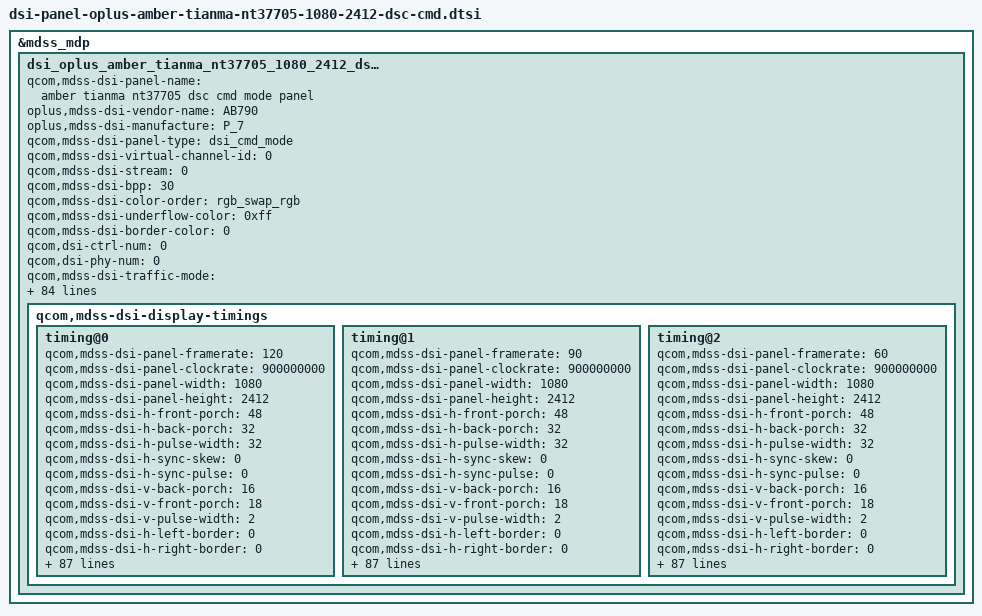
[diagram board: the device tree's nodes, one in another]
&mdss_mdp {
	dsi_oplus_amber_tianma_nt37705_1080_2412_dsc_cmd: qcom,mdss_dsi_oplus_amber_tianma_nt37705_1080_2412_dsc_cmd {
		qcom,mdss-dsi-panel-name = "amber tianma nt37705 dsc cmd mode panel";
		oplus,mdss-dsi-vendor-name = "AB790";
		oplus,mdss-dsi-manufacture = "P_7";
		qcom,mdss-dsi-panel-type = "dsi_cmd_mode";
		qcom,mdss-dsi-virtual-channel-id = <0>;
		qcom,mdss-dsi-stream = <0>;
		qcom,mdss-dsi-bpp = <30>;
		qcom,mdss-dsi-color-order = "rgb_swap_rgb";
		qcom,mdss-dsi-underflow-color = <0xff>;
		qcom,mdss-dsi-border-color = <0>;
		qcom,dsi-ctrl-num = <0>;
		qcom,dsi-phy-num = <0>;
		qcom,mdss-dsi-traffic-mode = "non_burst_sync_event";
		qcom,mdss-dsi-lane-map = "lane_map_0123";
		qcom,mdss-dsi-bllp-eof-power-mode;
		qcom,mdss-dsi-bllp-power-mode;
		qcom,mdss-dsi-lane-0-state;
		qcom,mdss-dsi-lane-1-state;
		qcom,mdss-dsi-lane-2-state;
		qcom,mdss-dsi-lane-3-state;
		qcom,mdss-dsi-dma-trigger = "trigger_sw";
		qcom,mdss-dsi-mdp-trigger = "none";
		qcom,mdss-dsi-reset-sequence = <1 10>, <0 10>, <1 20>;

		qcom,mdss-dsi-te-pin-select = <1>;
		qcom,mdss-dsi-te-dcs-command = <1>;
		qcom,mdss-dsi-te-check-enable;
		qcom,mdss-dsi-te-using-te-pin;
		qcom,mdss-dsi-lp11-init;
		qcom,mdss-dsi-wr-mem-start = <0x2c>;
		qcom,mdss-dsi-wr-mem-continue = <0x3c>;
		qcom,mdss-dsi-panel-hdr-enabled;
		qcom,mdss-dsi-panel-hdr-color-primaries = <15635 16450 34000 16000 13250 34500 7500 3000>;
		qcom,mdss-dsi-panel-peak-brightness = <5400000>;
		qcom,mdss-dsi-panel-blackness-level = <2000>;
		qcom,mdss-pan-physical-width-dimension = <70>;
		qcom,mdss-pan-physical-height-dimension = <155>;
		qcom,esd-check-enabled;
		qcom,mdss-dsi-panel-status-check-mode = "reg_read";
		qcom,mdss-dsi-panel-status-command = [06 01 00 01 05 00 01 0A];
		qcom,mdss-dsi-panel-status-command-state = "dsi_lp_mode";
		qcom,mdss-dsi-panel-status-value = <0x9C>;
		qcom,mdss-dsi-panel-status-read-length = <1>;
		oplus,mdss-dsi-panel-status-match-modes = <0x00000000>;
		qcom,dynamic-mode-switch-enabled;
		qcom,dynamic-mode-switch-type = "dynamic-resolution-switch-immediate";
		qcom,mdss-dsi-dma-schedule-line = <1>;
		qcom,mdss-dsi-dma-schedule-window = <10>;
		qcom,mdss-dsi-display-timings {
			timing@0 {
				qcom,mdss-dsi-panel-framerate = <120>;
				qcom,mdss-dsi-panel-clockrate = <900000000>;
				qcom,mdss-dsi-panel-width = <1080>;
				qcom,mdss-dsi-panel-height = <2412>;
				qcom,mdss-dsi-h-front-porch = <48>;
				qcom,mdss-dsi-h-back-porch = <32>;
				qcom,mdss-dsi-h-pulse-width = <32>;
				qcom,mdss-dsi-h-sync-skew = <0>;
				qcom,mdss-dsi-h-sync-pulse = <0>;
				qcom,mdss-dsi-v-back-porch = <16>;
				qcom,mdss-dsi-v-front-porch = <18>;
				qcom,mdss-dsi-v-pulse-width = <2>;
				qcom,mdss-dsi-h-left-border = <0>;
				qcom,mdss-dsi-h-right-border = <0>;
				qcom,mdss-dsi-v-top-border = <0>;
				qcom,mdss-dsi-v-bottom-border = <0>;
				qcom,mdss-dsi-panel-jitter = <0x4 0x1>;
				qcom,mdss-mdp-transfer-time-us = <6000>;

				oplus,fod-on-vblank = <0>;
				oplus,fod-off-vblank = <0>;
				qcom,mdss-dsi-timing-switch-command = [
					//120HZ
					39 00 00 00 00 00 02 2F 02
				];
				qcom,mdss-dsi-on-command = [
					39 01 00 00 00 00 05 FF AA 55 A5 83//Poer on Sequence优化
					39 01 00 00 00 00 02 6F 12
					39 01 00 00 00 00 02 FE 41
					39 01 00 00 00 00 05 FF AA 55 A5 81//写图等待时间
					39 01 00 00 00 00 02 6F 19
					39 01 00 00 00 00 02 FB 30
					39 01 00 00 00 00 02 6F 05//Source波形优化
					39 01 00 00 00 00 02 FE 3C
					39 01 00 00 00 00 06 F0 55 AA 52 08 06
					39 01 00 00 00 00 06 B2 00 38 37 37 37
					39 01 00 00 00 00 06 B3 37 38 38 38 38
					39 01 00 00 00 00 06 B8 00 38 37 37 37
					39 01 00 00 00 00 06 B9 37 38 38 38 38
					39 01 00 00 00 00 05 FF AA 55 A5 81//Idle 不开DMR
					39 01 00 00 00 00 02 6F 0E
					39 01 00 00 00 00 03 F5 2B 00
					39 01 00 00 00 00 02 6F 02//Vesa for Idle设定
					39 01 00 00 00 00 02 F9 04
					39 01 00 00 00 00 02 6F 0A
					39 01 00 00 00 00 02 FD 08
					39 01 00 00 00 00 05 FF AA 55 A5 80//AVC优化
					39 01 00 00 00 00 02 6F 0F
					39 01 00 00 00 00 02 FC 00
					39 01 00 00 00 00 02 6F 09
					39 01 00 00 00 00 03 FC FC F0
					39 01 00 00 00 00 05 FF AA 55 A5 80//OSC1=138.6M OSC2=138.6M
					39 01 00 00 00 00 02 6F 15
					39 01 00 00 00 00 03 F8 01 7E
					39 01 00 00 00 00 02 6F 31
					39 01 00 00 00 00 03 F8 01 1E
					39 01 00 00 00 00 02 6F 19//Gate波形优化
					39 01 00 00 00 00 02 F2 00
					39 01 00 00 00 00 02 6F 2D//AOD Timing优化
					39 01 00 00 00 00 02 FC 44
					39 01 00 00 00 00 02 6F 0A//Poer sequence调整
					39 01 00 00 00 00 04 F6 70 70 70
					39 01 00 00 00 00 02 6F 0E//Poer off sequence优化
					39 01 00 00 00 00 02 F6 70
					39 01 00 00 00 00 02 6F 2D//AOD on/off Speed up
					39 01 00 00 00 00 02 FC 44
					39 01 00 00 00 00 05 FF AA 55 A5 80
					39 01 00 00 00 00 02 6F 1A
					39 01 00 00 00 00 02 f4 55
					39 01 00 00 00 00 02 6F 01//Osc divider
					39 01 00 00 00 00 02 1F 06
					39 01 00 00 00 00 03 81 01 19//DPC Temperature
					39 01 00 00 00 00 02 5F 00//GIR OFF
					39 01 00 00 00 00 02 26 00//Gamma Set
					39 01 00 00 00 00 02 17 10//Command Mode
					39 01 00 00 00 00 05 2A 00 00 04 37//Set Column Address
					39 01 00 00 00 00 05 2B 00 00 09 6B//Set Ro Address
					39 01 00 00 00 00 02 2F 02//120Hz
					39 01 00 00 00 00 02 35 00//TE On
					39 01 00 00 00 00 03 44 00 00//Manual TE
					39 01 00 00 00 00 03 51 0D BB//Normal DBV
					39 01 00 00 00 00 02 6F 04//AOD DBV
					39 01 00 00 00 00 03 51 02 FF
					39 01 00 00 00 00 02 53 20//BC Control Enable
					39 01 00 00 00 00 03 90 03 03//Vesa On
					39 01 00 00 00 00 13 91 AB 28 00 0C C2 00 02 0E 01 1F 00 07 08 BB 08 7A 10 F0
					//Sleep out
					//39 01 00 00 00 00 03 51 FF FF
					39 01 00 00 00 00 06 F0 55 AA 52 08 01
					39 01 00 00 00 00 02 6F 0D
					39 01 00 00 00 00 02 D8 98
					39 01 00 00 00 00 02 6F 1E
					39 01 00 00 00 00 02 B9 19
					05 01 00 00 79 00 01 11
					05 01 00 00 00 00 01 29
				];
				qcom,mdss-dsi-off-command= [
					05 01 00 00 15 00 01 28
					05 01 00 00 79 00 01 10
				];
				qcom,mdss-dsi-post-on-backlight = [
					/* Display On */
					//39 00 00 40 00 00 04 FF 78 38 00
					//05 00 00 00 00 00 01 39
				];
				qcom,mdss-dsi-panel-info-switch-page-command = [
					/*read panel info switch page 01*/
					39 01 00 00 00 00 06 F0 55 AA 52 08 01
				];
				qcom,mdss-dsi-default-switch-page-command = [
					/*switch default page*/
					39 01 00 00 00 00 06 F0 55 AA 52 08 00
				];
				qcom,mdss-dsi-hbm-on-command = [
					//hbm
					39 00 00 40 09 00 02 53 20
					39 00 00 00 00 00 03 51 0E B0
				];
				qcom,mdss-dsi-normal-hbm-on-command = [
					//hbm
				];
				qcom,mdss-dsi-hbm-off-command = [
					39 00 00 00 00 00 03 51 0D BB
				];
				qcom,mdss-dsi-lhbm-tm-on-command = [
					//lhbm
					39 00 00 40 00 00 06 F0 55 AA 52 08 00
					39 00 00 40 00 00 02 6F 31
					39 00 00 40 00 00 02 DF 20
					39 00 00 40 00 00 06 F0 55 AA 52 08 02
					39 00 00 40 00 00 07 D0 00 00 00 00 00 00
					39 00 00 40 00 00 06 F0 55 AA 52 08 08
					39 00 00 40 00 00 02 6F 4A
					39 00 00 40 00 00 03 B8 08 00
					39 00 00 40 00 00 02 6F 4E
					39 00 00 40 00 00 03 B8 08 00
					39 00 00 40 00 00 06 F0 55 AA 52 08 00
					39 00 00 40 00 00 02 6F 4C
					39 00 00 40 00 00 03 DF 00 00
					39 00 00 40 00 00 0A 88 01 02 1C 08 91 00 00 00 00
					39 00 00 20 00 00 04 87 25 0F FF
				];
				qcom,mdss-dsi-lhbm-off-command = [
					//lhbm off
					39 00 00 00 00 00 02 87 00
				];
				qcom,mdss-dsi-aod-hbm-on-command = [

				];
				qcom,mdss-dsi-aod-hbm-off-command = [

				];
				qcom,mdss-dsi-aod-high-mode-command = [
					15 00 00 40 00 00 02 6F 04
					39 00 00 00 00 00 03 51 02 FF
				];
				qcom,mdss-dsi-aod-low-mode-command = [
					15 00 00 40 00 00 02 6F 04
					39 00 00 00 00 00 03 51 01 FF
				];
				qcom,mdss-dsi-lp1-command = [
					//AOD ON
					//15 00 00 40 00 00 02 2F 02
					05 01 00 40 00 00 01 39
					15 00 00 00 00 00 02 65 01
				];
				qcom,mdss-dsi-nolp-command = [
					//AOD OFF
					15 00 00 40 00 00 02 65 00
					05 00 00 40 00 00 01 38
					39 00 00 00 00 00 03 51 00 00
				];
				//qcom,mdss-dsi-seed-off-command = [

				//];
				//qcom,mdss-dsi-seed-3-command = [

				//];
				//qcom,mdss-dsi-seed-2-command = [

				//];
				//qcom,mdss-dsi-seed-1-command = [

				//];
				//qcom,mdss-dsi-seed-0-command = [

				//];
				qcom,mdss-dsi-hbm-enter-switch-command = [
					39 00 00 00 00 00 03 51 0D BB
				];
				qcom,mdss-dsi-hbm-exit-switch-command = [
					39 00 00 00 00 00 03 51 0D BB
				];
				qcom,mdss-dsi-osc-clk-mode0-command = [
				];
				qcom,mdss-dsi-osc-clk-mode1-command = [
				];
				qcom,mdss-dsi-ffc-mode0-command = [
					/* osc 121.5 */
					//39 00 00 40 00 00 04 FF 78 38 0F
					//39 00 00 40 00 00 02 6E 12
					//39 00 00 00 00 00 04 FF 78 38 00
				];
				qcom,mdss-dsi-ffc-mode1-command = [
					/* osc 128 */
					//39 00 00 40 00 00 04 FF 78 38 0F
					//39 00 00 40 00 00 02 6E 13
					//39 00 00 00 00 00 04 FF 78 38 00
				];
				qcom,mdss-dsi-timing-switch-command-state = "dsi_lp_mode";
				qcom,mdss-dsi-on-command-state = "dsi_lp_mode";
				qcom,mdss-dsi-panel-info-switch-page-command-state = "dsi_lp_mode";
				qcom,mdss-dsi-default-switch-page-command-state = "dsi_lp_mode";
				qcom,mdss-dsi-off-command-state = "dsi_lp_mode";
				qcom,mdss-dsi-hbm-on-command-state = "dsi_lp_mode";
				qcom,mdss-dsi-hbm-off-command-state = "dsi_lp_mode";
				qcom,mdss-dsi-lhbm-tm-on-command-state = "dsi_lp_mode";
				qcom,mdss-dsi-lhbm-off-command-state = "dsi_lp_mode";
				qcom,mdss-dsi-lp1-command-state = "dsi_lp_mode";
				qcom,mdss-dsi-nolp-command-state = "dsi_lp_mode";
				qcom,mdss-dsi-aod-high-mode-command-state = "dsi_lp_mode";
				qcom,mdss-dsi-aod-low-mode-command-state = "dsi_lp_mode";
				qcom,mdss-dsi-osc-clk-mode0-command-state = "dsi_lp_mode";
				qcom,mdss-dsi-osc-clk-mode1-command-state = "dsi_lp_mode";
				qcom,mdss-dsi-ffc-mode0-command-state = "dsi_lp_mode";
				qcom,mdss-dsi-ffc-mode1-command-state = "dsi_lp_mode";
				//qcom,mdss-dsi-seed-0-command-state = "dsi_lp_mode";
				//qcom,mdss-dsi-seed-1-command-state = "dsi_lp_mode";
				//qcom,mdss-dsi-seed-2-command-state = "dsi_lp_mode";
				//qcom,mdss-dsi-seed-3-command-state = "dsi_lp_mode";
				//qcom,mdss-dsi-seed-off-command-state = "dsi_lp_mode";
				qcom,compression-mode = "dsc";
				qcom,mdss-dsc-slice-height = <12>;
				qcom,mdss-dsc-slice-width = <540>;
				qcom,mdss-dsc-slice-per-pkt = <2>;
				qcom,mdss-dsc-bit-per-component = <10>;
				qcom,mdss-dsc-bit-per-pixel = <8>;
				qcom,mdss-dsc-block-prediction-enable;
				qcom,mdss-dsc-version = <0x11>;
				qcom,mdss-dsc-scr-version = <1>;
			};
			timing@1 {
				qcom,mdss-dsi-panel-framerate = <90>;
				qcom,mdss-dsi-panel-clockrate = <900000000>;
				qcom,mdss-dsi-panel-width = <1080>;
				qcom,mdss-dsi-panel-height = <2412>;
				qcom,mdss-dsi-h-front-porch = <48>;
				qcom,mdss-dsi-h-back-porch = <32>;
				qcom,mdss-dsi-h-pulse-width = <32>;
				qcom,mdss-dsi-h-sync-skew = <0>;
				qcom,mdss-dsi-h-sync-pulse = <0>;
				qcom,mdss-dsi-v-back-porch = <16>;
				qcom,mdss-dsi-v-front-porch = <18>;
				qcom,mdss-dsi-v-pulse-width = <2>;
				qcom,mdss-dsi-h-left-border = <0>;
				qcom,mdss-dsi-h-right-border = <0>;
				qcom,mdss-dsi-v-top-border = <0>;
				qcom,mdss-dsi-v-bottom-border = <0>;
				qcom,mdss-dsi-panel-jitter = <0x4 0x1>;
				qcom,mdss-mdp-transfer-time-us = <9000>;

				oplus,fod-on-vblank = <0>;
				oplus,fod-off-vblank = <0>;
				qcom,mdss-dsi-timing-switch-command = [
					//90HZ
					39 00 00 00 00 00 02 2F 01
				];
				qcom,mdss-dsi-on-command = [
					39 01 00 00 00 00 05 FF AA 55 A5 83//Poer on Sequence优化
					39 01 00 00 00 00 02 6F 12
					39 01 00 00 00 00 02 FE 41
					39 01 00 00 00 00 05 FF AA 55 A5 81//写图等待时间
					39 01 00 00 00 00 02 6F 19
					39 01 00 00 00 00 02 FB 30
					39 01 00 00 00 00 02 6F 05//Source波形优化
					39 01 00 00 00 00 02 FE 3C
					39 01 00 00 00 00 06 F0 55 AA 52 08 06
					39 01 00 00 00 00 06 B2 00 38 37 37 37
					39 01 00 00 00 00 06 B3 37 38 38 38 38
					39 01 00 00 00 00 06 B8 00 38 37 37 37
					39 01 00 00 00 00 06 B9 37 38 38 38 38
					39 01 00 00 00 00 05 FF AA 55 A5 81//Idle 不开DMR
					39 01 00 00 00 00 02 6F 0E
					39 01 00 00 00 00 03 F5 2B 00
					39 01 00 00 00 00 02 6F 02//Vesa for Idle设定
					39 01 00 00 00 00 02 F9 04
					39 01 00 00 00 00 02 6F 0A
					39 01 00 00 00 00 02 FD 08
					39 01 00 00 00 00 05 FF AA 55 A5 80//AVC优化
					39 01 00 00 00 00 02 6F 0F
					39 01 00 00 00 00 02 FC 00
					39 01 00 00 00 00 02 6F 09
					39 01 00 00 00 00 03 FC FC F0
					39 01 00 00 00 00 05 FF AA 55 A5 80//OSC1=138.6M OSC2=138.6M
					39 01 00 00 00 00 02 6F 15
					39 01 00 00 00 00 03 F8 01 7E
					39 01 00 00 00 00 02 6F 31
					39 01 00 00 00 00 03 F8 01 1E
					39 01 00 00 00 00 02 6F 19//Gate波形优化
					39 01 00 00 00 00 02 F2 00
					39 01 00 00 00 00 02 6F 2D//AOD Timing优化
					39 01 00 00 00 00 02 FC 44
					39 01 00 00 00 00 02 6F 0A//Poer sequence调整
					39 01 00 00 00 00 04 F6 70 70 70
					39 01 00 00 00 00 02 6F 0E//Poer off sequence优化
					39 01 00 00 00 00 02 F6 70
					39 01 00 00 00 00 02 6F 2D//AOD on/off Speed up
					39 01 00 00 00 00 02 FC 44
					39 01 00 00 00 00 05 FF AA 55 A5 80
					39 01 00 00 00 00 02 6F 1A
					39 01 00 00 00 00 02 f4 55
					39 01 00 00 00 00 02 6F 01//Osc divider
					39 01 00 00 00 00 02 1F 06
					39 01 00 00 00 00 03 81 01 19//DPC Temperature
					39 01 00 00 00 00 02 5F 00//GIR OFF
					39 01 00 00 00 00 02 26 00//Gamma Set
					39 01 00 00 00 00 02 17 10//Command Mode
					39 01 00 00 00 00 05 2A 00 00 04 37//Set Column Address
					39 01 00 00 00 00 05 2B 00 00 09 6B//Set Ro Address
					39 01 00 00 00 00 02 2F 01//90Hz
					39 01 00 00 00 00 02 35 00//TE On
					39 01 00 00 00 00 03 44 00 00//Manual TE
					39 01 00 00 00 00 03 51 0D BB//Normal DBV
					39 01 00 00 00 00 02 6F 04//AOD DBV
					39 01 00 00 00 00 03 51 02 FF
					39 01 00 00 00 00 02 53 20//BC Control Enable
					39 01 00 00 00 00 03 90 03 03//Vesa On
					39 01 00 00 00 00 13 91 AB 28 00 0C C2 00 02 0E 01 1F 00 07 08 BB 08 7A 10 F0
					//Sleep out
					//39 01 00 00 00 00 03 51 FF FF
					39 01 00 00 00 00 06 F0 55 AA 52 08 01
					39 01 00 00 00 00 02 6F 0D
					39 01 00 00 00 00 02 D8 98
					39 01 00 00 00 00 02 6F 1E
					39 01 00 00 00 00 02 B9 19
					05 01 00 00 79 00 01 11
					05 01 00 00 00 00 01 29
				];
				qcom,mdss-dsi-off-command= [
					05 01 00 00 15 00 01 28
					05 01 00 00 79 00 01 10
				];
				qcom,mdss-dsi-post-on-backlight = [
					/* Display On */
					//39 00 00 40 00 00 04 FF 78 38 00
					//05 00 00 00 00 00 01 39
				];
				qcom,mdss-dsi-panel-info-switch-page-command = [
					/*read panel info switch page 01*/
					39 01 00 00 00 00 06 F0 55 AA 52 08 01
				];
				qcom,mdss-dsi-default-switch-page-command = [
					/*switch default page*/
					39 01 00 00 00 00 06 F0 55 AA 52 08 00
				];
				qcom,mdss-dsi-hbm-on-command = [
					//hbm
					39 00 00 40 0C 00 02 53 20
					39 00 00 00 00 00 03 51 0E B0
				];
				qcom,mdss-dsi-normal-hbm-on-command = [
					//hbm
				];
				qcom,mdss-dsi-hbm-off-command = [
					39 00 00 00 00 00 03 51 0D BB
				];
				qcom,mdss-dsi-lhbm-tm-on-command = [
					//lhbm
					39 00 00 40 00 00 06 F0 55 AA 52 08 00
					39 00 00 40 00 00 02 6F 31
					39 00 00 40 00 00 02 DF 20
					39 00 00 40 00 00 06 F0 55 AA 52 08 02
					39 00 00 40 00 00 07 D0 00 00 00 00 00 00
					39 00 00 40 00 00 06 F0 55 AA 52 08 08
					39 00 00 40 00 00 02 6F 4A
					39 00 00 40 00 00 03 B8 08 00
					39 00 00 40 00 00 02 6F 4E
					39 00 00 40 00 00 03 B8 08 00
					39 00 00 40 00 00 06 F0 55 AA 52 08 00
					39 00 00 40 00 00 02 6F 4C
					39 00 00 40 00 00 03 DF 00 00
					39 00 00 40 00 00 0A 88 01 02 1C 08 91 00 00 00 00
					39 00 00 20 00 00 04 87 25 0F FF
				];
				qcom,mdss-dsi-lhbm-off-command = [
					//lhbm off
					39 00 00 00 00 00 02 87 00
				];
				qcom,mdss-dsi-aod-hbm-on-command = [

				];
				qcom,mdss-dsi-aod-hbm-off-command = [

				];
				qcom,mdss-dsi-aod-high-mode-command = [
					15 00 00 40 00 00 02 6F 04
					39 00 00 00 00 00 03 51 02 FF
				];
				qcom,mdss-dsi-aod-low-mode-command = [
					15 00 00 40 00 00 02 6F 04
					39 00 00 00 00 00 03 51 01 FF
				];
				qcom,mdss-dsi-lp1-command = [
					//AOD ON
					//15 00 00 40 00 00 02 2F 01
					05 01 00 40 00 00 01 39
					15 00 00 00 00 00 02 65 01
				];
				qcom,mdss-dsi-nolp-command = [
					//AOD OFF
					15 00 00 40 00 00 02 65 00
					05 00 00 40 00 00 01 38
					39 00 00 00 00 00 03 51 00 00
				];
				//qcom,mdss-dsi-seed-off-command = [

				//];
				//qcom,mdss-dsi-seed-3-command = [

				//];
				//qcom,mdss-dsi-seed-2-command = [

				//];
				//qcom,mdss-dsi-seed-1-command = [

				//];
				//qcom,mdss-dsi-seed-0-command = [

				//];
				qcom,mdss-dsi-hbm-enter-switch-command = [
					39 00 00 00 00 00 03 51 0D BB
				];
				qcom,mdss-dsi-hbm-exit-switch-command = [
					39 00 00 00 00 00 03 51 0D BB
				];
				qcom,mdss-dsi-osc-clk-mode0-command = [
				];
				qcom,mdss-dsi-osc-clk-mode1-command = [
				];
				qcom,mdss-dsi-ffc-mode0-command = [
					/* osc 121.5 */
					//39 00 00 40 00 00 04 FF 78 38 0F
					//39 00 00 40 00 00 02 6E 12
					//39 00 00 00 00 00 04 FF 78 38 00
				];
				qcom,mdss-dsi-ffc-mode1-command = [
					/* osc 128 */
					//39 00 00 40 00 00 04 FF 78 38 0F
					//39 00 00 40 00 00 02 6E 13
					//39 00 00 00 00 00 04 FF 78 38 00
				];
				qcom,mdss-dsi-timing-switch-command-state = "dsi_lp_mode";
				qcom,mdss-dsi-on-command-state = "dsi_lp_mode";
				qcom,mdss-dsi-panel-info-switch-page-command-state = "dsi_lp_mode";
				qcom,mdss-dsi-default-switch-page-command-state = "dsi_lp_mode";
				qcom,mdss-dsi-off-command-state = "dsi_lp_mode";
				qcom,mdss-dsi-hbm-on-command-state = "dsi_lp_mode";
				qcom,mdss-dsi-hbm-off-command-state = "dsi_lp_mode";
				qcom,mdss-dsi-lhbm-tm-on-command-state = "dsi_lp_mode";
				qcom,mdss-dsi-lhbm-off-command-state = "dsi_lp_mode";
				qcom,mdss-dsi-lp1-command-state = "dsi_lp_mode";
				qcom,mdss-dsi-nolp-command-state = "dsi_lp_mode";
				qcom,mdss-dsi-aod-high-mode-command-state = "dsi_lp_mode";
				qcom,mdss-dsi-aod-low-mode-command-state = "dsi_lp_mode";
				qcom,mdss-dsi-osc-clk-mode0-command-state = "dsi_lp_mode";
				qcom,mdss-dsi-osc-clk-mode1-command-state = "dsi_lp_mode";
				qcom,mdss-dsi-ffc-mode0-command-state = "dsi_lp_mode";
				qcom,mdss-dsi-ffc-mode1-command-state = "dsi_lp_mode";
				//qcom,mdss-dsi-seed-0-command-state = "dsi_lp_mode";
				//qcom,mdss-dsi-seed-1-command-state = "dsi_lp_mode";
				//qcom,mdss-dsi-seed-2-command-state = "dsi_lp_mode";
				//qcom,mdss-dsi-seed-3-command-state = "dsi_lp_mode";
				//qcom,mdss-dsi-seed-off-command-state = "dsi_lp_mode";
				qcom,compression-mode = "dsc";
				qcom,mdss-dsc-slice-height = <12>;
				qcom,mdss-dsc-slice-width = <540>;
				qcom,mdss-dsc-slice-per-pkt = <2>;
				qcom,mdss-dsc-bit-per-component = <10>;
				qcom,mdss-dsc-bit-per-pixel = <8>;
				qcom,mdss-dsc-block-prediction-enable;
				qcom,mdss-dsc-version = <0x11>;
				qcom,mdss-dsc-scr-version = <1>;
			};
			timing@2 {
				qcom,mdss-dsi-panel-framerate = <60>;
				qcom,mdss-dsi-panel-clockrate = <900000000>;
				qcom,mdss-dsi-panel-width = <1080>;
				qcom,mdss-dsi-panel-height = <2412>;
				qcom,mdss-dsi-h-front-porch = <48>;
				qcom,mdss-dsi-h-back-porch = <32>;
				qcom,mdss-dsi-h-pulse-width = <32>;
				qcom,mdss-dsi-h-sync-skew = <0>;
				qcom,mdss-dsi-h-sync-pulse = <0>;
				qcom,mdss-dsi-v-back-porch = <16>;
				qcom,mdss-dsi-v-front-porch = <18>;
				qcom,mdss-dsi-v-pulse-width = <2>;
				qcom,mdss-dsi-h-left-border = <0>;
				qcom,mdss-dsi-h-right-border = <0>;
				qcom,mdss-dsi-v-top-border = <0>;
				qcom,mdss-dsi-v-bottom-border = <0>;
				qcom,mdss-dsi-panel-jitter = <0x4 0x1>;
				qcom,mdss-mdp-transfer-time-us = <12000>;

				oplus,fod-on-vblank = <0>;
				oplus,fod-off-vblank = <0>;
				qcom,mdss-dsi-timing-switch-command = [
					//60HZ
					39 00 00 00 00 00 02 2F 00
				];
				qcom,mdss-dsi-on-command = [
					39 01 00 00 00 00 05 FF AA 55 A5 83//Poer on Sequence优化
					39 01 00 00 00 00 02 6F 12
					39 01 00 00 00 00 02 FE 41
					39 01 00 00 00 00 05 FF AA 55 A5 81//写图等待时间
					39 01 00 00 00 00 02 6F 19
					39 01 00 00 00 00 02 FB 30
					39 01 00 00 00 00 02 6F 05//Source波形优化
					39 01 00 00 00 00 02 FE 3C
					39 01 00 00 00 00 06 F0 55 AA 52 08 06
					39 01 00 00 00 00 06 B2 00 38 37 37 37
					39 01 00 00 00 00 06 B3 37 38 38 38 38
					39 01 00 00 00 00 06 B8 00 38 37 37 37
					39 01 00 00 00 00 06 B9 37 38 38 38 38
					39 01 00 00 00 00 05 FF AA 55 A5 81//Idle 不开DMR
					39 01 00 00 00 00 02 6F 0E
					39 01 00 00 00 00 03 F5 2B 00
					39 01 00 00 00 00 02 6F 02//Vesa for Idle设定
					39 01 00 00 00 00 02 F9 04
					39 01 00 00 00 00 02 6F 0A
					39 01 00 00 00 00 02 FD 08
					39 01 00 00 00 00 05 FF AA 55 A5 80//AVC优化
					39 01 00 00 00 00 02 6F 0F
					39 01 00 00 00 00 02 FC 00
					39 01 00 00 00 00 02 6F 09
					39 01 00 00 00 00 03 FC FC F0
					39 01 00 00 00 00 05 FF AA 55 A5 80//OSC1=138.6M OSC2=138.6M
					39 01 00 00 00 00 02 6F 15
					39 01 00 00 00 00 03 F8 01 7E
					39 01 00 00 00 00 02 6F 31
					39 01 00 00 00 00 03 F8 01 1E
					39 01 00 00 00 00 02 6F 19//Gate波形优化
					39 01 00 00 00 00 02 F2 00
					39 01 00 00 00 00 02 6F 2D//AOD Timing优化
					39 01 00 00 00 00 02 FC 44
					39 01 00 00 00 00 02 6F 0A//Poer sequence调整
					39 01 00 00 00 00 04 F6 70 70 70
					39 01 00 00 00 00 02 6F 0E//Poer off sequence优化
					39 01 00 00 00 00 02 F6 70
					39 01 00 00 00 00 02 6F 2D//AOD on/off Speed up
					39 01 00 00 00 00 02 FC 44
					39 01 00 00 00 00 05 FF AA 55 A5 80
					39 01 00 00 00 00 02 6F 1A
					39 01 00 00 00 00 02 f4 55
					39 01 00 00 00 00 02 6F 01//Osc divider
					39 01 00 00 00 00 02 1F 06
					39 01 00 00 00 00 03 81 01 19//DPC Temperature
					39 01 00 00 00 00 02 5F 00//GIR OFF
					39 01 00 00 00 00 02 26 00//Gamma Set
					39 01 00 00 00 00 02 17 10//Command Mode
					39 01 00 00 00 00 05 2A 00 00 04 37//Set Column Address
					39 01 00 00 00 00 05 2B 00 00 09 6B//Set Ro Address
					39 01 00 00 00 00 02 2F 00//60Hz
					39 01 00 00 00 00 02 35 00//TE On
					39 01 00 00 00 00 03 44 00 00//Manual TE
					39 01 00 00 00 00 03 51 0D BB//Normal DBV
					39 01 00 00 00 00 02 6F 04//AOD DBV
					39 01 00 00 00 00 03 51 02 FF
					39 01 00 00 00 00 02 53 20//BC Control Enable
					39 01 00 00 00 00 03 90 03 03//Vesa On
					39 01 00 00 00 00 13 91 AB 28 00 0C C2 00 02 0E 01 1F 00 07 08 BB 08 7A 10 F0
					//Sleep out
					//39 01 00 00 00 00 03 51 FF FF
					39 01 00 00 00 00 06 F0 55 AA 52 08 01
					39 01 00 00 00 00 02 6F 0D
					39 01 00 00 00 00 02 D8 98
					39 01 00 00 00 00 02 6F 1E
					39 01 00 00 00 00 02 B9 19
					05 01 00 00 79 00 01 11
					05 01 00 00 00 00 01 29
				];
				qcom,mdss-dsi-off-command= [
					05 01 00 00 15 00 01 28
					05 01 00 00 79 00 01 10
				];
				qcom,mdss-dsi-post-on-backlight = [
					/* Display On */
					//39 00 00 40 00 00 04 FF 78 38 00
					//05 00 00 00 00 00 01 39
				];
				qcom,mdss-dsi-panel-info-switch-page-command = [
					/*read panel info switch page 01*/
					39 01 00 00 00 00 06 F0 55 AA 52 08 01
				];
				qcom,mdss-dsi-default-switch-page-command = [
					/*switch default page*/
					39 01 00 00 00 00 06 F0 55 AA 52 08 00
				];
				qcom,mdss-dsi-hbm-on-command = [
					//hbm
					39 00 00 40 11 00 02 53 20
					39 00 00 00 00 00 03 51 0E B0
				];
				qcom,mdss-dsi-normal-hbm-on-command = [
					//hbm
				];
				qcom,mdss-dsi-hbm-off-command = [
					39 00 00 00 00 00 03 51 0D BB
				];
				qcom,mdss-dsi-lhbm-tm-on-command = [
					//lhbm
					39 00 00 40 00 00 06 F0 55 AA 52 08 00
					39 00 00 40 00 00 02 6F 31
					39 00 00 40 00 00 02 DF 20
					39 00 00 40 00 00 06 F0 55 AA 52 08 02
					39 00 00 40 00 00 07 D0 00 00 00 00 00 00
					39 00 00 40 00 00 06 F0 55 AA 52 08 08
					39 00 00 40 00 00 02 6F 4A
					39 00 00 40 00 00 03 B8 08 00
					39 00 00 40 00 00 02 6F 4E
					39 00 00 40 00 00 03 B8 08 00
					39 00 00 40 00 00 06 F0 55 AA 52 08 00
					39 00 00 40 00 00 02 6F 4C
					39 00 00 40 00 00 03 DF 00 00
					39 00 00 40 00 00 0A 88 01 02 1C 08 91 00 00 00 00
					39 00 00 20 00 00 04 87 25 0F FF
				];
				qcom,mdss-dsi-lhbm-off-command = [
					//lhbm off
					39 00 00 00 00 00 02 87 00
				];
				qcom,mdss-dsi-aod-hbm-on-command = [

				];
				qcom,mdss-dsi-aod-hbm-off-command = [

				];
				qcom,mdss-dsi-aod-high-mode-command = [
					15 00 00 40 00 00 02 6F 04
					39 00 00 00 00 00 03 51 02 FF
				];
				qcom,mdss-dsi-aod-low-mode-command = [
					15 00 00 40 00 00 02 6F 04
					39 00 00 00 00 00 03 51 01 FF
				];
				qcom,mdss-dsi-lp1-command = [
					//AOD ON
					//15 00 00 40 00 00 02 2F 00
					05 01 00 40 00 00 01 39
					15 00 00 00 00 00 02 65 01
				];
				qcom,mdss-dsi-nolp-command = [
					//AOD OFF
					15 00 00 40 00 00 02 65 00
					05 00 00 40 00 00 01 38
					39 00 00 00 00 00 03 51 00 00
				];
				//qcom,mdss-dsi-seed-off-command = [

				//];
				//qcom,mdss-dsi-seed-3-command = [

				//];
				//qcom,mdss-dsi-seed-2-command = [

				//];
				//qcom,mdss-dsi-seed-1-command = [

				//];
				//qcom,mdss-dsi-seed-0-command = [

				//];
				qcom,mdss-dsi-hbm-enter-switch-command = [
					39 00 00 00 00 00 03 51 0D BB
				];
				qcom,mdss-dsi-hbm-exit-switch-command = [
					39 00 00 00 00 00 03 51 0D BB
				];
				qcom,mdss-dsi-osc-clk-mode0-command = [
				];
				qcom,mdss-dsi-osc-clk-mode1-command = [
				];
				qcom,mdss-dsi-ffc-mode0-command = [
					/* osc 121.5 */
					//39 00 00 40 00 00 04 FF 78 38 0F
					//39 00 00 40 00 00 02 6E 12
					//39 00 00 00 00 00 04 FF 78 38 00
				];
				qcom,mdss-dsi-ffc-mode1-command = [
					/* osc 128 */
					//39 00 00 40 00 00 04 FF 78 38 0F
					//39 00 00 40 00 00 02 6E 13
					//39 00 00 00 00 00 04 FF 78 38 00
				];
				qcom,mdss-dsi-timing-switch-command-state = "dsi_lp_mode";
				qcom,mdss-dsi-on-command-state = "dsi_lp_mode";
				qcom,mdss-dsi-panel-info-switch-page-command-state = "dsi_lp_mode";
				qcom,mdss-dsi-default-switch-page-command-state = "dsi_lp_mode";
				qcom,mdss-dsi-off-command-state = "dsi_lp_mode";
				qcom,mdss-dsi-hbm-on-command-state = "dsi_lp_mode";
				qcom,mdss-dsi-hbm-off-command-state = "dsi_lp_mode";
				qcom,mdss-dsi-lhbm-tm-on-command-state = "dsi_lp_mode";
				qcom,mdss-dsi-lhbm-off-command-state = "dsi_lp_mode";
				qcom,mdss-dsi-lp1-command-state = "dsi_lp_mode";
				qcom,mdss-dsi-nolp-command-state = "dsi_lp_mode";
				qcom,mdss-dsi-aod-high-mode-command-state = "dsi_lp_mode";
				qcom,mdss-dsi-aod-low-mode-command-state = "dsi_lp_mode";
				qcom,mdss-dsi-osc-clk-mode0-command-state = "dsi_lp_mode";
				qcom,mdss-dsi-osc-clk-mode1-command-state = "dsi_lp_mode";
				qcom,mdss-dsi-ffc-mode0-command-state = "dsi_lp_mode";
				qcom,mdss-dsi-ffc-mode1-command-state = "dsi_lp_mode";
				//qcom,mdss-dsi-seed-0-command-state = "dsi_lp_mode";
				//qcom,mdss-dsi-seed-1-command-state = "dsi_lp_mode";
				//qcom,mdss-dsi-seed-2-command-state = "dsi_lp_mode";
				//qcom,mdss-dsi-seed-3-command-state = "dsi_lp_mode";
				//qcom,mdss-dsi-seed-off-command-state = "dsi_lp_mode";
				qcom,compression-mode = "dsc";
				qcom,mdss-dsc-slice-height = <12>;
				qcom,mdss-dsc-slice-width = <540>;
				qcom,mdss-dsc-slice-per-pkt = <2>;
				qcom,mdss-dsc-bit-per-component = <10>;
				qcom,mdss-dsc-bit-per-pixel = <8>;
				qcom,mdss-dsc-block-prediction-enable;
				qcom,mdss-dsc-version = <0x11>;
				qcom,mdss-dsc-scr-version = <1>;
			};
		};
	};
};



&dsi_oplus_amber_tianma_nt37705_1080_2412_dsc_cmd {
	qcom,panel-supply-entries = <&dsi_panel_oplus_pwr_supply_amber_tm>;
	qcom,mdss-dsi-panel-controller = <&mdss_dsi0>;
	qcom,mdss-dsi-bl-pmic-control-type = "bl_ctrl_dcs";
	qcom,mdss-dsi-bl-inverted-dbv;
	qcom,mdss-dsi-bl-min-level = <1>;
	qcom,mdss-dsi-bl-max-level = <4094>;
	qcom,mdss-brightness-max-level = <4094>;
	oplus,dsi-bl-normal-max-level = <3515>;
	oplus,dsi-brightness-normal-max-level = <3515>;
	oplus,dsi-brightness-default-level = <2047>;
	/* ofp config */
	oplus,ofp-fp-type = <0x08>;
        oplus,ofp-need-to-bypass-gc;
        oplus,ofp-need-to-bypass-igc;
	oplus,ofp-need-to-wait-data-before-aod-on;
	qcom,platform-te-gpio = <&tlmm 99 0>;
	qcom,platform-reset-gpio = <&tlmm 98 0>;
	qcom,ulps-enabled;
	qcom,dsi-select-clocks = "pll_byte_clk0", "pll_dsi_clk0";
	/* serial num config */
	oplus,dsi-serial-number-enabled;
	oplus,dsi-serial-number-index= <0>;
	oplus,dsi-serial-number-switch-page;
	//oplus,dsi-serial-number-multi-reg;
	//oplus,dsi-serial-number-multi-regs = [00 01 02 03 04 05 06];
	oplus,dsi-serial-number-reg= <0xD7>;
	oplus,dsi-serial-number-read-count= <7>;
	/* osc */
	oplus,ffc-enabled;
	oplus,ffc-handle;
	oplus,clk-osc-sequence =
		<978000000 121500>,
		<978000000 128000>;
	oplus,dsi-fod-brightness = <36 0xed>,
			<60 0xec>,
			<90 0xeb>,
			<140 0xea>,
			<200 0xe8>,
			<300 0xe4>,
			<458 0xe0>,
			<605 0xdb>,
			<743 0xcf>,
			<912 0xc8>,
			<1062 0xbf>,
			<1187 0xb6>,
			<1393 0xa0>,
			<1611 0x9b>,
			<1787 0x92>,
			<2000 0x8b>,
			<2200 0x80>,
			<2400 0x70>,
			<2600 0x60>,
			<2800 0x50>,
			<3000 0x4A>,
			<3200 0x40>,
			<3400 0x36>,
			<3515 0x2e>;

	qcom,mdss-dsi-display-timings {
		timing@0 {
				qcom,mdss-dsi-panel-phy-timings = [00 1E 08 07 18 16 08 08 08 02 04 00 1A 0D];
				qcom,display-topology = <1 1 1>;
				qcom,default-topology-index = <0>;
		};
		timing@1 {
				qcom,mdss-dsi-panel-phy-timings = [00 1E 08 07 18 16 08 08 08 02 04 00 1A 0D];
				qcom,display-topology = <1 1 1>;
				qcom,default-topology-index = <0>;
		};
		timing@2 {
				qcom,mdss-dsi-panel-phy-timings = [00 1E 08 07 18 16 08 08 08 02 04 00 1A 0D];
				qcom,display-topology = <1 1 1>;
				qcom,default-topology-index = <0>;
		};
	};
};

&dsi_oplus_amber_tianma_nt37705_1080_2412_dsc_cmd {
	qcom,panel_voltage_vddi_name = "vddio";
	qcom,panel_voltage_vddi = <0 1800000 1850000 1950000>;
	qcom,panel_voltage_vddr_name = "vddio";
	qcom,panel_voltage_vddr = <1 1800000 1850000 1950000>;
};
